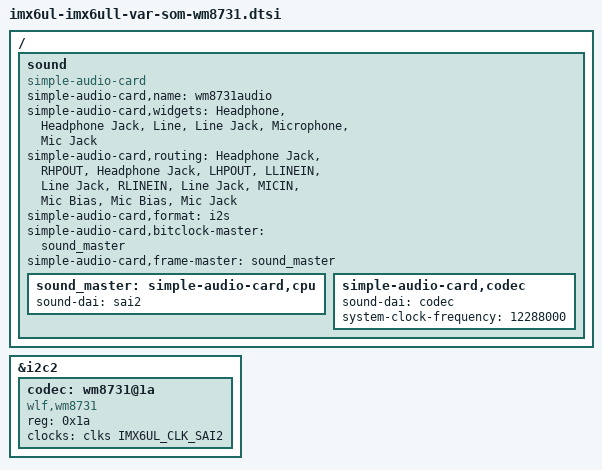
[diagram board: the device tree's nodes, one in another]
/*
 * Copyright (C) 2024 Variscite Ltd. - https://www.variscite.com
 *
 * This program is free software; you can redistribute it and/or modify
 * it under the terms of the GNU General Public License version 2 as
 * published by the Free Software Foundation.
 */

/ {
	/delete-node/ sound;

	sound {
		compatible = "simple-audio-card";
		simple-audio-card,name = "wm8731audio";
		simple-audio-card,widgets =
			"Headphone", "Headphone Jack",
			"Line", "Line Jack",
			"Microphone", "Mic Jack";
		simple-audio-card,routing =
			"Headphone Jack", "RHPOUT",
			"Headphone Jack", "LHPOUT",
			"LLINEIN", "Line Jack",
			"RLINEIN", "Line Jack",
			"MICIN", "Mic Bias",
			"Mic Bias", "Mic Jack";
		simple-audio-card,format = "i2s";
		simple-audio-card,bitclock-master = <&sound_master>;
		simple-audio-card,frame-master = <&sound_master>;

		sound_master: simple-audio-card,cpu {
			sound-dai = <&sai2>;
		};

		simple-audio-card,codec {
			sound-dai = <&codec>;
			system-clock-frequency = <12288000>;
		};
	};
};

&i2c2 {
	/delete-node/ wm8904@1a;

	codec: wm8731@1a {
		#sound-dai-cells = <0>;
		compatible = "wlf,wm8731";
		reg = <0x1a>;
		clocks = <&clks IMX6UL_CLK_SAI2>;
		clock-names = "mclk";
		status = "okay";
	};
};
